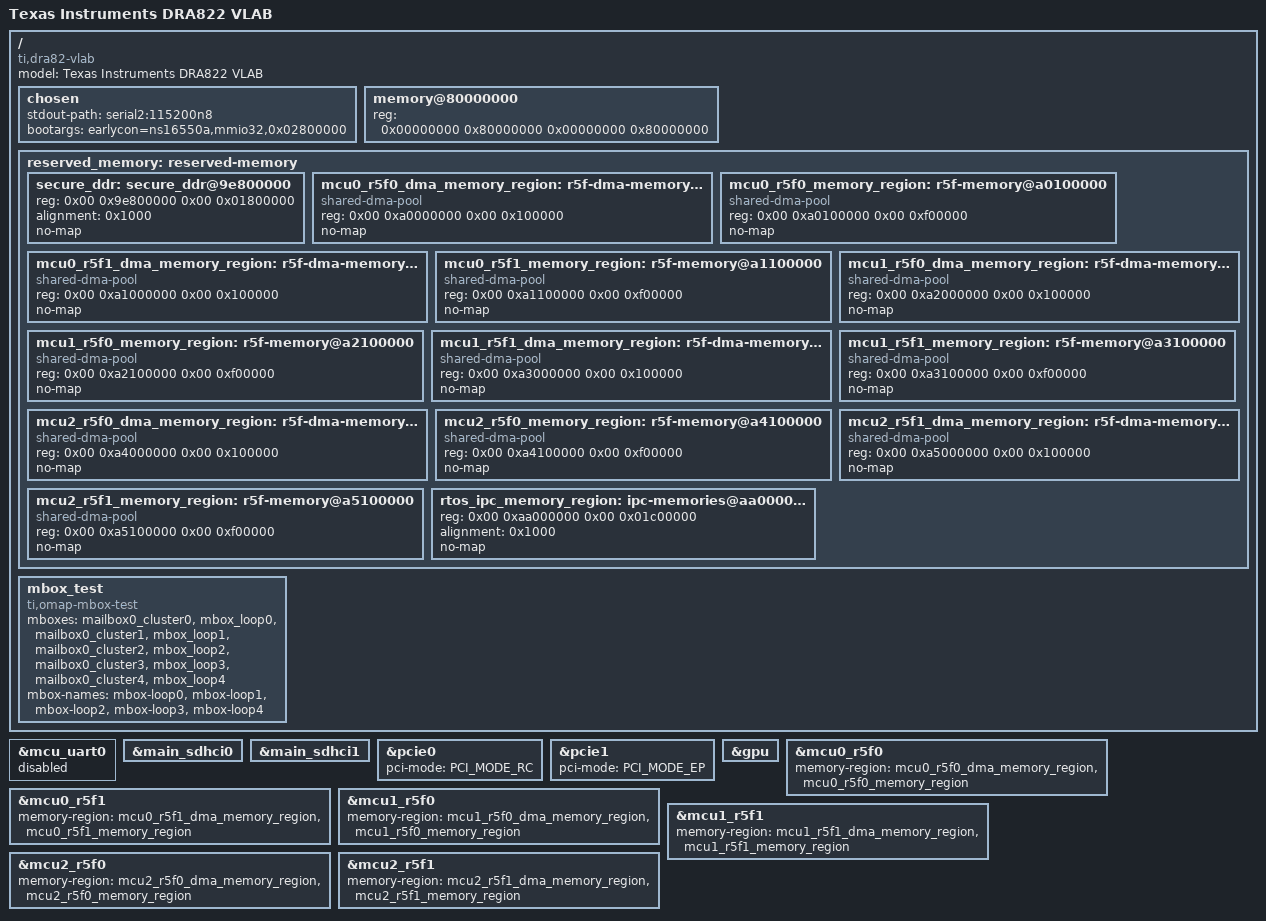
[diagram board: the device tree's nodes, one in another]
// SPDX-License-Identifier: GPL-2.0
/*
 * Copyright (C) 2016-2018 Texas Instruments Incorporated - http://www.ti.com/
 */

/dts-v1/;

#include "k3-dra82.dtsi"
#include <dt-bindings/pci/pci.h>

/ {
	compatible =  "ti,dra82-vlab", "ti,dra822";
	model = "Texas Instruments DRA822 VLAB";

	chosen {
		stdout-path = "serial2:115200n8";
		bootargs = "earlycon=ns16550a,mmio32,0x02800000";
	};

	memory@80000000 {
		device_type = "memory";
		/* 2G RAM */
		reg = <0x00000000 0x80000000 0x00000000 0x80000000>;

	};

	reserved_memory: reserved-memory {
		#address-cells = <2>;
		#size-cells = <2>;
		ranges;

		secure_ddr: secure_ddr@9e800000 {
			reg = <0x00 0x9e800000 0x00 0x01800000>; /* for OP-TEE */
			alignment = <0x1000>;
			no-map;
		};

		mcu0_r5f0_dma_memory_region: r5f-dma-memory@a0000000 {
			compatible = "shared-dma-pool";
			reg = <0x00 0xa0000000 0x00 0x100000>;
			no-map;
		};

		mcu0_r5f0_memory_region: r5f-memory@a0100000 {
			compatible = "shared-dma-pool";
			reg = <0x00 0xa0100000 0x00 0xf00000>;
			no-map;
		};

		mcu0_r5f1_dma_memory_region: r5f-dma-memory@a1000000 {
			compatible = "shared-dma-pool";
			reg = <0x00 0xa1000000 0x00 0x100000>;
			no-map;
		};

		mcu0_r5f1_memory_region: r5f-memory@a1100000 {
			compatible = "shared-dma-pool";
			reg = <0x00 0xa1100000 0x00 0xf00000>;
			no-map;
		};

		mcu1_r5f0_dma_memory_region: r5f-dma-memory@a2000000 {
			compatible = "shared-dma-pool";
			reg = <0x00 0xa2000000 0x00 0x100000>;
			no-map;
		};

		mcu1_r5f0_memory_region: r5f-memory@a2100000 {
			compatible = "shared-dma-pool";
			reg = <0x00 0xa2100000 0x00 0xf00000>;
			no-map;
		};

		mcu1_r5f1_dma_memory_region: r5f-dma-memory@a3000000 {
			compatible = "shared-dma-pool";
			reg = <0x00 0xa3000000 0x00 0x100000>;
			no-map;
		};

		mcu1_r5f1_memory_region: r5f-memory@a3100000 {
			compatible = "shared-dma-pool";
			reg = <0x00 0xa3100000 0x00 0xf00000>;
			no-map;
		};

		mcu2_r5f0_dma_memory_region: r5f-dma-memory@a4000000 {
			compatible = "shared-dma-pool";
			reg = <0x00 0xa4000000 0x00 0x100000>;
			no-map;
		};

		mcu2_r5f0_memory_region: r5f-memory@a4100000 {
			compatible = "shared-dma-pool";
			reg = <0x00 0xa4100000 0x00 0xf00000>;
			no-map;
		};

		mcu2_r5f1_dma_memory_region: r5f-dma-memory@a5000000 {
			compatible = "shared-dma-pool";
			reg = <0x00 0xa5000000 0x00 0x100000>;
			no-map;
		};

		mcu2_r5f1_memory_region: r5f-memory@a5100000 {
			compatible = "shared-dma-pool";
			reg = <0x00 0xa5100000 0x00 0xf00000>;
			no-map;
		};

		rtos_ipc_memory_region: ipc-memories@aa000000 {
			reg = <0x00 0xaa000000 0x00 0x01c00000>;
			alignment = <0x1000>;
			no-map;
		};
	};

	mbox_test {
		compatible = "ti,omap-mbox-test";
		mboxes = <&mailbox0_cluster0 &mbox_loop0>,
			 <&mailbox0_cluster1 &mbox_loop1>,
			 <&mailbox0_cluster2 &mbox_loop2>,
			 <&mailbox0_cluster3 &mbox_loop3>,
			 <&mailbox0_cluster4 &mbox_loop4>;
		mbox-names = "mbox-loop0", "mbox-loop1", "mbox-loop2",
			     "mbox-loop3", "mbox-loop4";
	};
};

&mcu_uart0 {
	/* Wakeup UART is used by System firmware */
	status = "disabled";
};

&main_sdhci0 {
	status = "okay";
};

&main_sdhci1 {
	status = "okay";
};

&pcie0 {
	pci-mode = <PCI_MODE_RC>;
	status = "okay";
};

&pcie1 {
	pci-mode = <PCI_MODE_EP>;
	status = "okay";
};

&gpu {
	status = "okay";
};

#include "k3-dss-640x480-port0-dpi.dtsi"
#include "k3-dss-640x480-port1-dpi.dtsi"

&mcu0_r5f0 {
	memory-region = <&mcu0_r5f0_dma_memory_region>,
			<&mcu0_r5f0_memory_region>;
};

&mcu0_r5f1 {
	memory-region = <&mcu0_r5f1_dma_memory_region>,
			<&mcu0_r5f1_memory_region>;
};

&mcu1_r5f0 {
	memory-region = <&mcu1_r5f0_dma_memory_region>,
			<&mcu1_r5f0_memory_region>;
};

&mcu1_r5f1 {
	memory-region = <&mcu1_r5f1_dma_memory_region>,
			<&mcu1_r5f1_memory_region>;
};

&mcu2_r5f0 {
	memory-region = <&mcu2_r5f0_dma_memory_region>,
			<&mcu2_r5f0_memory_region>;
};

&mcu2_r5f1 {
	memory-region = <&mcu2_r5f1_dma_memory_region>,
			<&mcu2_r5f1_memory_region>;
};
